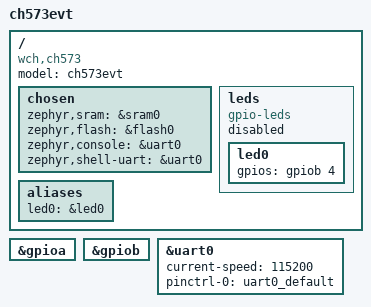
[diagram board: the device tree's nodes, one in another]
/*
 * Copyright (c) 2026 Lucy Wong
 * SPDX-License-Identifier: Apache-2.0
 */

/dts-v1/;

#include <wch/ch573/ch573x8.dtsi>
#include "ch573evt-pinctrl.dtsi"

/ {
	model = "ch573evt";
	compatible = "wch,ch573";

	chosen {
		zephyr,sram = &sram0;
		zephyr,flash = &flash0;
		zephyr,console = &uart0;
		zephyr,shell-uart = &uart0;
	};

	leds {
		compatible = "gpio-leds";
		status = "disabled";

		led0: led0 {
			gpios = <&gpiob 4 GPIO_ACTIVE_HIGH>;
		};
	};

	aliases {
		led0 = &led0;
	};
};

&gpioa {
	status = "okay";
};

&gpiob {
	status = "okay";
};

&uart0 {
	status = "okay";
	current-speed = <115200>;
	pinctrl-0 = <&uart0_default>;
	pinctrl-names = "default";
};
